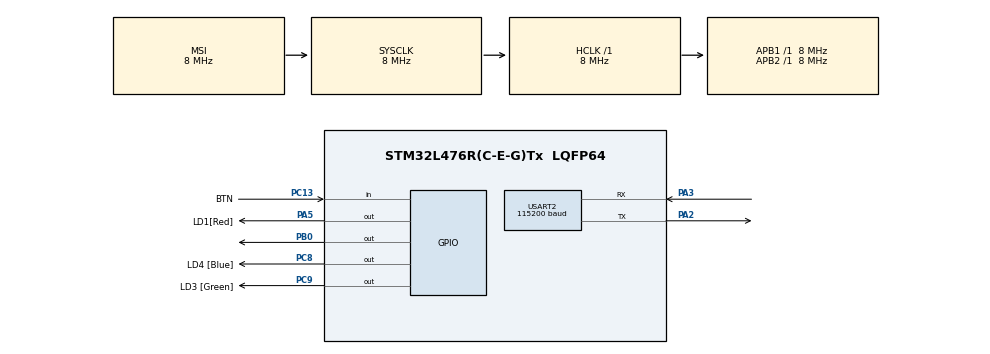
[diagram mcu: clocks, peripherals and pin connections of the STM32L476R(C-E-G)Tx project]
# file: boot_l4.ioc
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Mcu.Family=STM32L4
Mcu.Name=STM32L476R(C-E-G)Tx
Mcu.Package=LQFP64
NVIC.PriorityGroup=NVIC_PRIORITYGROUP_4
PA13\ (JTMS-SWDIO).GPIO_Label=TMS_SWDIO
PA13\ (JTMS-SWDIO).Mode=Serial_Wire
PA13\ (JTMS-SWDIO).Signal=SYS_JTMS-SWDIO
PA14\ (JTCK-SWCLK).GPIO_Label=TCK_SWCLK
PA14\ (JTCK-SWCLK).Mode=Serial_Wire
PA14\ (JTCK-SWCLK).Signal=SYS_JTCK-SWCLK
PA2.Mode=Asynchronous
PA2.Signal=USART2_TX
PA3.Mode=Asynchronous
PA3.Signal=USART2_RX
PA5.GPIO_Label=LD1[Red]
PA5.Signal=GPIO_Output
PB0.Signal=GPIO_Output
PC13.GPIO_Label=BTN
PC13.Signal=GPIO_Input
PC8.GPIO_Label=LD4 [Blue]
PC8.Signal=GPIO_Output
PC9.GPIO_Label=LD3 [Green]
PC9.Signal=GPIO_Output
PH0-OSC_IN\ (PH0).Mode=HSE-External-Oscillator
PH0-OSC_IN\ (PH0).Signal=RCC_OSC_IN
PH1-OSC_OUT\ (PH1).Mode=HSE-External-Oscillator
PH1-OSC_OUT\ (PH1).Signal=RCC_OSC_OUT
ProjectManager.HeapSize=0x200
ProjectManager.StackSize=0x400
ProjectManager.TargetToolchain=CMake
RCC.ADCFreq_Value=32000000
RCC.AHBFreq_Value=8000000
RCC.APB1Freq_Value=8000000
RCC.APB1TimFreq_Value=8000000
RCC.APB2Freq_Value=8000000
RCC.APB2TimFreq_Value=8000000
RCC.CortexFreq_Value=8000000
RCC.HCLKFreq_Value=8000000
RCC.HSE_VALUE=8000000
RCC.HSI_VALUE=16000000
RCC.LSE_VALUE=32768
RCC.MSIClockRange=RCC_MSIRANGE_7
RCC.MSI_VALUE=8000000
RCC.SYSCLKFreq_VALUE=8000000
RCC.USBFreq_Value=32000000
RCC.VCOOutputFreq_Value=64000000
USART2.AutoBaudRateEnableParam=UART_ADVFEATURE_AUTOBAUDRATE_DISABLE
USART2.BaudRate=115200
USART2.DMADisableonRxErrorParam=ADVFEATURE_DMA_ENABLEONRXERROR
USART2.DataInvertParam=ADVFEATURE_DATAINV_DISABLE
USART2.MSBFirstParam=ADVFEATURE_MSBFIRST_DISABLE
USART2.Mode=MODE_TX_RX
USART2.OneBitSampling=UART_ONE_BIT_SAMPLE_DISABLE
USART2.OverSampling=UART_OVERSAMPLING_16
USART2.OverrunDisableParam=ADVFEATURE_OVERRUN_ENABLE
USART2.Parity=PARITY_NONE
USART2.RxPinLevelInvertParam=ADVFEATURE_RXINV_DISABLE
USART2.StopBits=STOPBITS_1
USART2.SwapParam=ADVFEATURE_SWAP_DISABLE
USART2.TxPinLevelInvertParam=ADVFEATURE_TXINV_DISABLE
USART2.VirtualMode-Asynchronous=VM_ASYNC
USART2.WordLength=WORDLENGTH_8B
board=STM32VLDISCOVERY

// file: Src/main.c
/* USER CODE BEGIN Header */
/**
  ******************************************************************************
  * @file           : main.c
  * @brief          : Main program body
  ******************************************************************************
  * @attention
  *
  * Copyright (c) 2024 STMicroelectronics.
  * All rights reserved.
  *
  * This software is licensed under terms that can be found in the LICENSE file
  * in the root directory of this software component.
  * If no LICENSE file comes with this software, it is provided AS-IS.
  *
  ******************************************************************************
  */
/* USER CODE END Header */
#include "main.h"

/* USER CODE BEGIN Includes */

#include "xmodem.h"
#include "flash.h"

/* USER CODE END Includes */

UART_HandleTypeDef huart2;

void SystemClock_Config(void);
static void MX_GPIO_Init(void);
static void MX_USART2_UART_Init(void);

int main(void)
{

  /* MCU Configuration--------------------------------------------------------*/

  /* Reset of all peripherals, Initializes the Flash interface and the Systick. */
  HAL_Init();

  /* Configure the system clock */
  SystemClock_Config();

  /* Initialize all configured peripherals */
  MX_GPIO_Init();
  MX_USART2_UART_Init();
  /* USER CODE BEGIN 2 */

  FLASH_Init();

  uart_transmit_str((uint8_t*)"\n\r================================\n\r");
  uart_transmit_str((uint8_t*)"UART Bootloader\n\r");
  uart_transmit_str((uint8_t*)"___________________________\n\r");
  uart_transmit_str((uint8_t*)"================================\n\r\n\r");

  if(!HAL_GPIO_ReadPin(BTN_GPIO_Port, BTN_Pin))
  {
    uart_transmit_str((uint8_t*)"Jumping to user application...\n\r");
    //flash_jump_to_app();
  }

  /* USER CODE END 2 */

  /* Infinite loop */
  while (1)
  {

    /* USER CODE BEGIN 3 */

    HAL_GPIO_WritePin(GPIOA, LD1_Pin, GPIO_PIN_SET);

		uart_transmit_str((uint8_t*)"Please send a new binary file with Xmodem protocol to update the firmware.\n\r");
    xmodem_receive();
    /* We only exit the xmodem protocol, if there are any errors.
     * In that case, notify the user and start over. */
    uart_transmit_str((uint8_t*)"\n\rFailed... Please try again.\n\r");

  }
  /* USER CODE END 3 */
}

void SystemClock_Config(void)
{
  RCC_OscInitTypeDef RCC_OscInitStruct = {0};
  RCC_ClkInitTypeDef RCC_ClkInitStruct = {0};

  /** Configure the main internal regulator output voltage
  */
  if (HAL_PWREx_ControlVoltageScaling(PWR_REGULATOR_VOLTAGE_SCALE1) != HAL_OK)
  {
    Error_Handler();
  }

  /** Initializes the RCC Oscillators according to the specified parameters
  * in the RCC_OscInitTypeDef structure.
  */
  RCC_OscInitStruct.OscillatorType = RCC_OSCILLATORTYPE_MSI;
  RCC_OscInitStruct.MSIState = RCC_MSI_ON;
  RCC_OscInitStruct.MSICalibrationValue = 0;
  RCC_OscInitStruct.MSIClockRange = RCC_MSIRANGE_7;
  RCC_OscInitStruct.PLL.PLLState = RCC_PLL_NONE;
  if (HAL_RCC_OscConfig(&RCC_OscInitStruct) != HAL_OK)
  {
    Error_Handler();
  }

  /** Initializes the CPU, AHB and APB buses clocks
  */
  RCC_ClkInitStruct.ClockType = RCC_CLOCKTYPE_HCLK|RCC_CLOCKTYPE_SYSCLK
                              |RCC_CLOCKTYPE_PCLK1|RCC_CLOCKTYPE_PCLK2;
  RCC_ClkInitStruct.SYSCLKSource = RCC_SYSCLKSOURCE_MSI;
  RCC_ClkInitStruct.AHBCLKDivider = RCC_SYSCLK_DIV1;
  RCC_ClkInitStruct.APB1CLKDivider = RCC_HCLK_DIV1;
  RCC_ClkInitStruct.APB2CLKDivider = RCC_HCLK_DIV1;

  if (HAL_RCC_ClockConfig(&RCC_ClkInitStruct, FLASH_LATENCY_0) != HAL_OK)
  {
    Error_Handler();
  }
}

static void MX_USART2_UART_Init(void)
{

  huart2.Instance = USART2;
  huart2.Init.BaudRate = 115200;
  huart2.Init.WordLength = UART_WORDLENGTH_8B;
  huart2.Init.StopBits = UART_STOPBITS_1;
  huart2.Init.Parity = UART_PARITY_NONE;
  huart2.Init.Mode = UART_MODE_TX_RX;
  huart2.Init.HwFlowCtl = UART_HWCONTROL_NONE;
  huart2.Init.OverSampling = UART_OVERSAMPLING_16;
  huart2.Init.OneBitSampling = UART_ONE_BIT_SAMPLE_DISABLE;
  huart2.AdvancedInit.AdvFeatureInit = UART_ADVFEATURE_NO_INIT;
  if (HAL_UART_Init(&huart2) != HAL_OK)
  {
    Error_Handler();
  }

}

static void MX_GPIO_Init(void)
{
  GPIO_InitTypeDef GPIO_InitStruct = {0};

  /* GPIO Ports Clock Enable */
  __HAL_RCC_GPIOC_CLK_ENABLE();
  __HAL_RCC_GPIOH_CLK_ENABLE();
  __HAL_RCC_GPIOA_CLK_ENABLE();
  __HAL_RCC_GPIOB_CLK_ENABLE();

  /*Configure GPIO pin Output Level */
  HAL_GPIO_WritePin(LD1_GPIO_Port, LD1_Pin, GPIO_PIN_RESET);

  /*Configure GPIO pin Output Level */
  HAL_GPIO_WritePin(GPIOB, GPIO_PIN_0, GPIO_PIN_RESET);

  /*Configure GPIO pin Output Level */
  HAL_GPIO_WritePin(GPIOC, LD4_Pin|LD3_Pin, GPIO_PIN_RESET);

  /*Configure GPIO pin : BTN_Pin */
  GPIO_InitStruct.Pin = BTN_Pin;
  GPIO_InitStruct.Mode = GPIO_MODE_INPUT;
  GPIO_InitStruct.Pull = GPIO_NOPULL;
  HAL_GPIO_Init(BTN_GPIO_Port, &GPIO_InitStruct);

  /*Configure GPIO pin : LD1_Pin */
  GPIO_InitStruct.Pin = LD1_Pin;
  GPIO_InitStruct.Mode = GPIO_MODE_OUTPUT_PP;
  GPIO_InitStruct.Pull = GPIO_NOPULL;
  GPIO_InitStruct.Speed = GPIO_SPEED_FREQ_LOW;
  HAL_GPIO_Init(LD1_GPIO_Port, &GPIO_InitStruct);

  /*Configure GPIO pin : PB0 */
  GPIO_InitStruct.Pin = GPIO_PIN_0;
  GPIO_InitStruct.Mode = GPIO_MODE_OUTPUT_PP;
  GPIO_InitStruct.Pull = GPIO_NOPULL;
  GPIO_InitStruct.Speed = GPIO_SPEED_FREQ_LOW;
  HAL_GPIO_Init(GPIOB, &GPIO_InitStruct);

  /*Configure GPIO pins : LD4_Pin LD3_Pin */
  GPIO_InitStruct.Pin = LD4_Pin|LD3_Pin;
  GPIO_InitStruct.Mode = GPIO_MODE_OUTPUT_PP;
  GPIO_InitStruct.Pull = GPIO_NOPULL;
  GPIO_InitStruct.Speed = GPIO_SPEED_FREQ_LOW;
  HAL_GPIO_Init(GPIOC, &GPIO_InitStruct);

}

void Error_Handler(void)
{
  __disable_irq();
  while (1)
  {
  }
}
